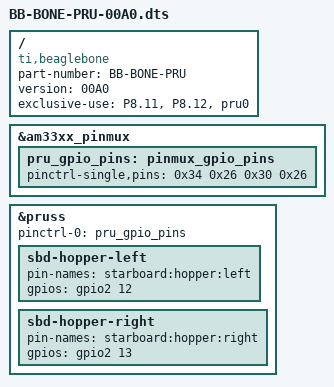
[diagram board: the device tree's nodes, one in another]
/*
* pru dts file BB-BONE-PRU-00A0.dts
*/
/dts-v1/;
/plugin/;

/ {
        compatible = "ti,beaglebone", "ti,beaglebone-black";

        /* identification */
        part-number = "BB-BONE-PRU";
        version = "00A0";

        /* state the resources this cape uses */
        exclusive-use =
                /* the pin header uses */
                "P8.11", /* pru0: pr1_pru0_pru_r30_15 */
                "P8.12", /* pru0: pr1_pru0_pru_r30_14 */
                /* the hardware IP uses */
                "pru0";

        /* pinmux */
        fragment@0 {
                target = <&am33xx_pinmux>;
                __overlay__ {
                pru_gpio_pins: pinmux_gpio_pins {
                                pinctrl-single,pins = <
                                        0x34 0x26 /* P8.11 GPIO1_13: MODE6 | OUTPUT */
                                        0x30 0x26 /* P8.12 GPIO1_12: MODE6 | OUTPUT */
                                >;
                        };
                };
        };

        fragment@1 {
                target = <&pruss>;
                __overlay__ {
                        pinctrl-names = "default";
                        pinctrl-0 = <&pru_gpio_pins>;
                        status = "okay";
                        sbd-hopper-left {
                                pin-names = "starboard:hopper:left";
                                gpios = <&gpio2 12 0>;
                        };
                        sbd-hopper-right {
                                pin-names = "starboard:hopper:right";
                                gpios = <&gpio2 13 0>;
                        };
                };
        };
};
